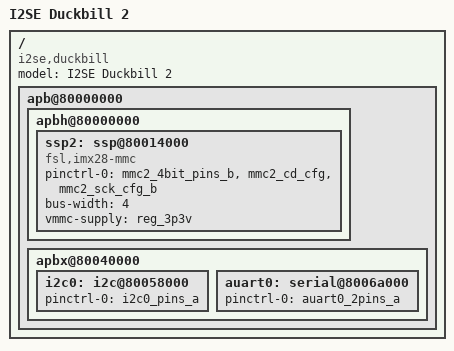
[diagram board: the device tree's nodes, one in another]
/*
 * Copyright (C) 2015-2016 I2SE GmbH <info@i2se.com>
 *
 * The code contained herein is licensed under the GNU General Public
 * License. You may obtain a copy of the GNU General Public License
 * Version 2 or later at the following locations:
 *
 * http://www.opensource.org/licenses/gpl-license.html
 * http://www.gnu.org/copyleft/gpl.html
 */

/dts-v1/;
#include "imx28-duckbill-2-common.dtsi"

/ {
	model = "I2SE Duckbill 2";
	compatible = "i2se,duckbill", "fsl,imx28";

	apb@80000000 {
		apbh@80000000 {
			ssp2: ssp@80014000 {
				compatible = "fsl,imx28-mmc";
				pinctrl-names = "default";
				pinctrl-0 = <&mmc2_4bit_pins_b
					&mmc2_cd_cfg &mmc2_sck_cfg_b>;
				bus-width = <4>;
				vmmc-supply = <&reg_3p3v>;
				status = "okay";
			};
		};

		apbx@80040000 {
			i2c0: i2c@80058000 {
				pinctrl-names = "default";
				pinctrl-0 = <&i2c0_pins_a>;
				status = "okay";
			};

			auart0: serial@8006a000 {
				pinctrl-names = "default";
				pinctrl-0 = <&auart0_2pins_a>;
				status = "okay";
			};
		};
	};
};
